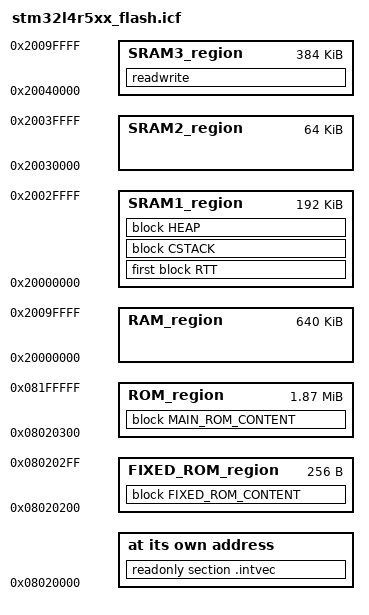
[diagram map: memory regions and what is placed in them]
/*###ICF### Section handled by ICF editor, don't touch! ****/
/*-Editor annotation file-*/
/* IcfEditorFile="$TOOLKIT_DIR$\config\ide\IcfEditor\cortex_v1_0.xml" */
/*-Specials-*/
define symbol __ICFEDIT_intvec_start__ = 0x08020000;
/*-Memory Regions-*/
define symbol __ICFEDIT_region_ROM_start__ = 0x08020300;
define symbol __ICFEDIT_region_ROM_end__   = 0x081FFFFF;
define symbol __ICFEDIT_region_RAM_start__ = 0x20000000;
define symbol __ICFEDIT_region_RAM_end__   = 0x2009FFFF;

/*-Sizes-*/
define symbol __ICFEDIT_size_cstack__ = 0x11000;
define symbol __ICFEDIT_size_heap__   = 0x10000;
/**** End of ICF editor section. ###ICF###*/

/****************** ELVIS Product Header Alloc ****************/
define symbol __FIXED_region_ROM_start__   = 0x08020200;
define symbol __FIXED_region_ROM_end__     = 0x080202FF;
/**************************************************************/
define symbol __region_SRAM1_start__  = 0x20000000;
define symbol __region_SRAM1_end__    = 0x2002FFFF;
define symbol __region_SRAM2_start__  = 0x20030000;
define symbol __region_SRAM2_end__    = 0x2003FFFF;
define symbol __region_SRAM3_start__  = 0x20040000;
define symbol __region_SRAM3_end__    = 0x2009FFFF;

define memory mem with size = 4G;
define region ROM_region      = mem:[from __ICFEDIT_region_ROM_start__   to __ICFEDIT_region_ROM_end__];
define region RAM_region      = mem:[from __ICFEDIT_region_RAM_start__   to __ICFEDIT_region_RAM_end__];
define region SRAM1_region    = mem:[from __region_SRAM1_start__   to __region_SRAM1_end__];
define region SRAM2_region    = mem:[from __region_SRAM2_start__   to __region_SRAM2_end__];
define region SRAM3_region    = mem:[from __region_SRAM3_start__   to __region_SRAM3_end__];

/****************** ELVIS Product Header Alloc ***********************/
define region FIXED_ROM_region= mem:[from __FIXED_region_ROM_start__   to __FIXED_region_ROM_end__];
/*********************************************************************/
define block CSTACK    with alignment = 8, size = __ICFEDIT_size_cstack__   { };
define block HEAP      with alignment = 8, size = __ICFEDIT_size_heap__     { };

/* SEGGER RTT (Real Time Transfer) for SystemView support */
/* See https://devzone.nordicsemi.com/f/nordic-q-a/10381/how-to-configure-rtt-with-a-fixed-address-in-iar */
define symbol Size_RTT = 0x1000;
define block RTT       with alignment = 8, size = Size_RTT                  { section RTT_section };

initialize by copy { readwrite };
do not initialize  { section .noinit };

place at address mem:__ICFEDIT_intvec_start__ { readonly section .intvec };

/***** ELVIS - Product Header Infomation Constants *********/

define block FIXED_ROM_CONTENT with fixed order
{
	readonly section applicationDk,
	readonly section applicationVersion,
    readonly section code_crc,
	readonly section instrumentType,
	readonly section ROM_length_used
};

keep { section applicationDk };
keep { section applicationVersion };
keep { section code_crc };
keep { section instrumentType };
keep { section ROM_length_used };

/***** ELVIS - Checksum Markers *********/

define block MAIN_ROM_CONTENT with fixed order
{
	readonly section crc_start_mark,
	readonly,
	readonly section crc_end_mark
};

keep { section crc_start_mark };
keep { section crc_end_mark };

/********** ELVIS - Placement in ROM and RAM *************/

/*place in ROM_region { block ROM_CONTENT };*/
place in ROM_region { block MAIN_ROM_CONTENT };
place in FIXED_ROM_region { block FIXED_ROM_CONTENT };
place in SRAM1_region { first block RTT, block CSTACK, block HEAP };
/* SRAM2 RESERVED for bootloader app API */
place in SRAM3_region { readwrite };
place in SRAM3_region { };
                        
/* See ELVIS for any explanation/information */

                        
